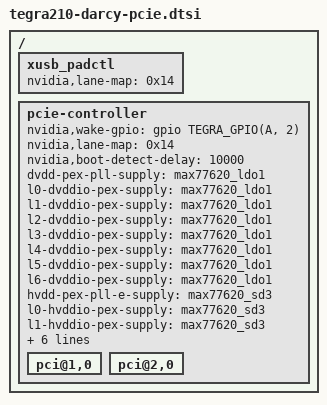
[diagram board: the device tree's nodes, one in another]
/*
 * arch/arm64/boot/dts/tegra210-platforms/tegra210-darcy-pci.dtsi
 *
 * Copyright (c) 2015, NVIDIA CORPORATION.  All rights reserved.
 *
 * This program is free software; you can redistribute it and/or modify
 * it under the terms of the GNU General Public License as published by
 * the Free Software Foundation; version 2 of the License.
 *
 * This program is distributed in the hope that it will be useful, but WITHOUT
 * ANY WARRANTY; without even the implied warranty of MERCHANTABILITY or
 * FITNESS FOR A PARTICULAR PURPOSE.  See the GNU General Public License for
 * more details.
 *
 * You should have received a copy of the GNU General Public License along
 * with this program; if not, write to the Free Software Foundation, Inc.,
 * 51 Franklin Street, Fifth Floor, Boston, MA  02110-1301, USA.
 *
 */
/ {
	xusb_padctl {
		nvidia,lane-map = <0x14>;
	};

	pcie-controller {
		nvidia,wake-gpio = <&gpio TEGRA_GPIO(A, 2) 0>;
		nvidia,lane-map = <0x14>;
		nvidia,boot-detect-delay = <10000>;
		dvdd-pex-pll-supply = <&max77620_ldo1>;
		l0-dvddio-pex-supply = <&max77620_ldo1>;
		l1-dvddio-pex-supply = <&max77620_ldo1>;
		l2-dvddio-pex-supply = <&max77620_ldo1>;
		l3-dvddio-pex-supply = <&max77620_ldo1>;
		l4-dvddio-pex-supply = <&max77620_ldo1>;
		l5-dvddio-pex-supply = <&max77620_ldo1>;
		l6-dvddio-pex-supply = <&max77620_ldo1>;
		hvdd-pex-pll-e-supply = <&max77620_sd3>;
		l0-hvddio-pex-supply = <&max77620_sd3>;
		l1-hvddio-pex-supply = <&max77620_sd3>;
		l2-hvddio-pex-supply = <&max77620_sd3>;
		l3-hvddio-pex-supply = <&max77620_sd3>;
		l4-hvddio-pex-supply = <&max77620_sd3>;
		l5-hvddio-pex-supply = <&max77620_sd3>;
		l6-hvddio-pex-supply = <&max77620_sd3>;
		vddio-pex-ctl-supply = <&max77620_sd3>;
		status = "okay";

		pci@1,0 {
			status = "okay";
		};

		pci@2,0 {
			status = "okay";
		};
	};
};
